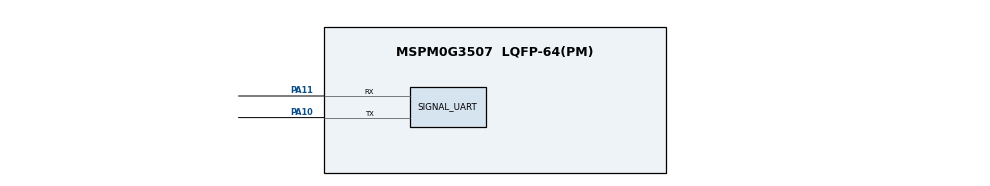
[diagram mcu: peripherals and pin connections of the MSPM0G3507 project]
/** PROFILE_06_FULL_SIGNAL: dual ADC + DAC + comparator capture + UART. */
//@cliArgs --device "MSPM0G350X" --package "LQFP-64(PM)" --part "Default"
//@v2CliArgs --device "MSPM0G3507" --package "LQFP-64(PM)"
// @cliArgs --board /ti/boards/LP_MSPM0G3507 --rtos nortos

const ProjectConfig = scripting.addModule("/ti/project_config/ProjectConfig");
const Board = scripting.addModule("/ti/driverlib/Board");
const SYSCTL = scripting.addModule("/ti/driverlib/SYSCTL");

ProjectConfig.genLibCMSIS = true;
const ADC12 = scripting.addModule("/ti/driverlib/ADC12", {}, false);
const ADC_A = ADC12.addInstance();
const ADC_B = ADC12.addInstance();
const DAC12 = scripting.addModule("/ti/driverlib/DAC12");
const TIMER = scripting.addModule("/ti/driverlib/TIMER", {}, false);
const ADC_TIMER = TIMER.addInstance();
const DAC_TIMER = TIMER.addInstance();
const CAPTURE = scripting.addModule("/ti/driverlib/CAPTURE", {}, false);
const SIGNAL_CAPTURE = CAPTURE.addInstance();
const COMP = scripting.addModule("/ti/driverlib/COMP", {}, false);
const SIGNAL_COMP = COMP.addInstance();
const UART = scripting.addModule("/ti/driverlib/UART", {}, false);
const SIGNAL_UART = UART.addInstance();

ADC_A.$name = "SIGNAL_ADC_A";
ADC_A.sampClkSrc = "DL_ADC12_CLOCK_ULPCLK";
ADC_A.adcMem0chansel = "DL_ADC12_INPUT_CHAN_2";
ADC_A.sampleTime0 = "62.5ns";
ADC_A.powerDownMode = "DL_ADC12_POWER_DOWN_MODE_MANUAL";
ADC_A.trigSrc = "DL_ADC12_TRIG_SRC_EVENT";
ADC_A.repeatMode = true;
ADC_A.adcMem0trig = "DL_ADC12_TRIGGER_MODE_TRIGGER_NEXT";
ADC_A.subChanID = 1;
ADC_A.configureDMA = true;
ADC_A.sampCnt = 1;
ADC_A.enabledDMATriggers = ["DL_ADC12_DMA_MEM0_RESULT_LOADED"];
ADC_A.enabledInterrupts = ["DL_ADC12_INTERRUPT_DMA_DONE"];
ADC_A.peripheral.$assign = "ADC0";
ADC_A.peripheral.adcPin2.$assign = "PA25";
ADC_A.DMA_CHANNEL.$name = "SIGNAL_ADC_A_DMA";
ADC_A.DMA_CHANNEL.peripheral.$assign = "DMA_CH0";
ADC_A.DMA_CHANNEL.addressMode = "f2b";
ADC_A.DMA_CHANNEL.srcLength = "HALF_WORD";
ADC_A.DMA_CHANNEL.dstLength = "HALF_WORD";
ADC_A.DMA_CHANNEL.transferMode = "SINGLE";

ADC_B.$name = "SIGNAL_ADC_B";
ADC_B.sampClkSrc = "DL_ADC12_CLOCK_ULPCLK";
ADC_B.adcMem0chansel = "DL_ADC12_INPUT_CHAN_2";
ADC_B.sampleTime0 = "62.5ns";
ADC_B.powerDownMode = "DL_ADC12_POWER_DOWN_MODE_MANUAL";
ADC_B.trigSrc = "DL_ADC12_TRIG_SRC_EVENT";
ADC_B.repeatMode = true;
ADC_B.adcMem0trig = "DL_ADC12_TRIGGER_MODE_TRIGGER_NEXT";
ADC_B.subChanID = 2;
ADC_B.configureDMA = true;
ADC_B.sampCnt = 1;
ADC_B.enabledDMATriggers = ["DL_ADC12_DMA_MEM0_RESULT_LOADED"];
ADC_B.enabledInterrupts = ["DL_ADC12_INTERRUPT_DMA_DONE"];
ADC_B.peripheral.$assign = "ADC1";
ADC_B.peripheral.adcPin2.$assign = "PA17";
ADC_B.DMA_CHANNEL.$name = "SIGNAL_ADC_B_DMA";
ADC_B.DMA_CHANNEL.peripheral.$assign = "DMA_CH2";
ADC_B.DMA_CHANNEL.addressMode = "f2b";
ADC_B.DMA_CHANNEL.srcLength = "HALF_WORD";
ADC_B.DMA_CHANNEL.dstLength = "HALF_WORD";
ADC_B.DMA_CHANNEL.transferMode = "SINGLE";

ADC_TIMER.$name = "SIGNAL_DUAL_ADC_TIMER";
ADC_TIMER.timerClkSrc = "BUSCLK";
ADC_TIMER.timerPeriod = "10us";
ADC_TIMER.timerMode = "PERIODIC";
ADC_TIMER.event1PublisherChannel = 1;
ADC_TIMER.event1ControllerInterruptEn = ["ZERO_EVENT"];
ADC_TIMER.event2PublisherChannel = 2;
ADC_TIMER.event2ControllerInterruptEn = ["ZERO_EVENT"];
ADC_TIMER.peripheral.$assign = "TIMG0";

const mfpGate = system.clockTree["MFPCLKGATE"];
mfpGate.enable = true;
DAC12.dacConfigureDMA = true;
DAC12.dacFIFOEn = true;
DAC12.dacFIFOThresh = "TWO_QTRS_EMPTY";
DAC12.dacFIFOTrigger = "HWTRIG0";
DAC12.sub0ChanID = 3;
DAC12.dacEnabledInterrupts = ["DMA_DONE"];
DAC12.dacSampleTimerEn = false;
DAC12.dacOutputPinEn = true;
DAC12.dacAmplifier = "ON";
DAC12.DMA_CHANNEL.$name = "SIGNAL_DAC_DMA";
DAC12.DMA_CHANNEL.peripheral.$assign = "DMA_CH1";
DAC12.DMA_CHANNEL.transferMode = "FULL_CH_REPEAT_SINGLE";
DAC12.DMA_CHANNEL.addressMode = "b2f";
DAC12.DMA_CHANNEL.srcLength = "HALF_WORD";
DAC12.DMA_CHANNEL.dstLength = "HALF_WORD";

DAC_TIMER.$name = "SIGNAL_DAC_TIMER";
DAC_TIMER.timerClkSrc = "BUSCLK";
DAC_TIMER.timerPeriod = "10us";
DAC_TIMER.timerMode = "PERIODIC";
DAC_TIMER.event1PublisherChannel = 3;
DAC_TIMER.event1ControllerInterruptEn = ["ZERO_EVENT"];
DAC_TIMER.peripheral.$assign = "TIMG6";

SIGNAL_CAPTURE.$name = "SIGNAL_CAPTURE";
SIGNAL_CAPTURE.timerClkSrc = "BUSCLK";
SIGNAL_CAPTURE.timerClkDiv = 1;
SIGNAL_CAPTURE.timerPeriod = "2ms";
SIGNAL_CAPTURE.captSelect = "Trigger";
SIGNAL_CAPTURE.subscriberPort = "FSUB0";
SIGNAL_CAPTURE.subscriberChannel = 4;
SIGNAL_CAPTURE.interrupts = ["CC0_DN", "ZERO"];
SIGNAL_CAPTURE.peripheral.$assign = "TIMG7";

SIGNAL_COMP.$name = "SIGNAL_COMP";
SIGNAL_COMP.selectOutputFilter = "DL_COMP_FILTER_DELAY_1200";
SIGNAL_COMP.compMode = "DL_COMP_MODE_ULP";
SIGNAL_COMP.hysteresis = "DL_COMP_HYSTERESIS_30";
SIGNAL_COMP.vSource = "DL_COMP_REF_SOURCE_VDDA_DAC";
SIGNAL_COMP.controlSelect = "DL_COMP_DAC_CONTROL_SW";
SIGNAL_COMP.pubChanID = 4;
SIGNAL_COMP.enabledEvents = ["DL_COMP_EVENT_OUTPUT_EDGE"];
SIGNAL_COMP.channelEnable = ["NEG"];
SIGNAL_COMP.peripheral.$assign = "COMP0";
SIGNAL_COMP.peripheral.compPinNeg0.$assign = "PA27";

SIGNAL_UART.$name = "SIGNAL_UART";
SIGNAL_UART.profile = "CONFIG_PROFILE_1";
SIGNAL_UART.peripheral.$assign = "UART0";
SIGNAL_UART.uartClkSrc = "BUSCLK";
SIGNAL_UART.targetBaudRate = 115200;
SIGNAL_UART.enableInternalLoopback = false;
SIGNAL_UART.enableFIFO = true;
SIGNAL_UART.peripheral.txPin.$assign = "PA10";
SIGNAL_UART.peripheral.rxPin.$assign = "PA11";

SYSCTL.MFPCLKEn = true;
SYSCTL.forceDefaultClkConfig = true;
SYSCTL.clockTreeEn = true;
